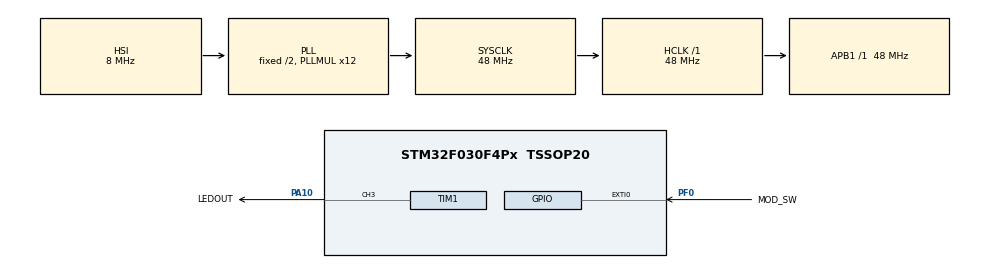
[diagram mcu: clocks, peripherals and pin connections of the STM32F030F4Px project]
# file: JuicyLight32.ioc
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Dma.Request0=TIM1_CH3/UP
Dma.TIM1_CH3/UP.0.Direction=DMA_MEMORY_TO_PERIPH
Dma.TIM1_CH3/UP.0.Instance=DMA1_Channel5
Dma.TIM1_CH3/UP.0.MemDataAlignment=DMA_MDATAALIGN_BYTE
Dma.TIM1_CH3/UP.0.MemInc=DMA_MINC_ENABLE
Dma.TIM1_CH3/UP.0.Mode=DMA_NORMAL
Dma.TIM1_CH3/UP.0.PeriphDataAlignment=DMA_PDATAALIGN_HALFWORD
Dma.TIM1_CH3/UP.0.PeriphInc=DMA_PINC_DISABLE
Dma.TIM1_CH3/UP.0.Priority=DMA_PRIORITY_HIGH
Mcu.Family=STM32F0
Mcu.Name=STM32F030F4Px
Mcu.Package=TSSOP20
Mcu.UserConstants=PWM_PERIOD,59;PWM_HI,29;PWM_LO,14;TIM_PERIOD_80uS,4000;TIM_PERIOD_8mS,8000;TIM_PRESC_1uS,47
NVIC.DMA1_Channel4_5_IRQn=true\:0\:0\:false\:false\:true\:false\:true
NVIC.EXTI0_1_IRQn=true\:0\:0\:false\:false\:true\:true\:true
NVIC.TIM3_IRQn=true\:0\:0\:false\:false\:true\:true\:true
PA10.GPIO_Label=LEDOUT
PA10.Signal=S_TIM1_CH3
PA13.Mode=Serial_Wire
PA13.Signal=SYS_SWDIO
PA14.Mode=Serial_Wire
PA14.Signal=SYS_SWCLK
PF0-OSC_IN.GPIO_Label=MOD_SW
PF0-OSC_IN.GPIO_ModeDefaultEXTI=GPIO_MODE_IT_RISING_FALLING
PF0-OSC_IN.Signal=GPXTI0
ProjectManager.HeapSize=0x200
ProjectManager.StackSize=0x400
ProjectManager.TargetToolchain=STM32CubeIDE
RCC.AHBFreq_Value=48000000
RCC.APB1Freq_Value=48000000
RCC.APB1TimFreq_Value=48000000
RCC.HCLKFreq_Value=48000000
RCC.PLLMUL=RCC_PLL_MUL12
RCC.SYSCLKFreq_VALUE=48000000
RCC.SYSCLKSource=RCC_SYSCLKSOURCE_PLLCLK
SH.S_TIM1_CH3.0=TIM1_CH3,PWM Generation3 CH3
TIM1.AutoReloadPreload=TIM_AUTORELOAD_PRELOAD_ENABLE
TIM1.Channel-PWM\ Generation3\ CH3=TIM_CHANNEL_3
TIM1.OCPolarity_3=TIM_OCPOLARITY_LOW
TIM1.Period=PWM_PERIOD
TIM14.Period=TIM_PERIOD_80uS
TIM3.Period=TIM_PERIOD_8mS
TIM3.Prescaler=TIM_PRESC_1uS
VP_TIM14_VS_ClockSourceINT.Mode=Enable_Timer
VP_TIM1_VS_ClockSourceINT.Mode=Internal
VP_TIM3_VS_ClockSourceINT.Mode=Internal
board=custom

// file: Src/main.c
/* USER CODE BEGIN Header */
/**
  ******************************************************************************
  * @file           : main.c
  * @brief          : Main program body
  ******************************************************************************
  * @attention
  *
  * <h2><center>&copy; Copyright (c) 2019 STMicroelectronics.
  * All rights reserved.</center></h2>
  *
  * This software component is licensed by ST under BSD 3-Clause license,
  * the "License"; You may not use this file except in compliance with the
  * License. You may obtain a copy of the License at:
  *                        opensource.org/licenses/BSD-3-Clause
  *
  ******************************************************************************
  */
/* USER CODE END Header */

#include "main.h"

TIM_HandleTypeDef htim1;
TIM_HandleTypeDef htim3;
TIM_HandleTypeDef htim14;
DMA_HandleTypeDef hdma_tim1_ch3_up;

/* USER CODE BEGIN PV */
#if LEDTYPE == RGBW
const LEDDATA LEDTable[COLOR_COUNT] = {
		//			R		G		B		W
		{.rgbw = {.r=LOFF,.g=LOFF,.b=LOFF,.w=LOFF}},//COLOR_OFF,
		{.rgbw = {.r=LMAX,.g=LOFF,.b=LOFF,.w=LOFF}},//COLOR_RED,
		{.rgbw = {.r=LOFF,.g=LOFF,.b=LMAX,.w=LOFF}},//COLOR_BLUE,
		{.rgbw = {.r=LOFF,.g=LMAX,.b=LOFF,.w=LOFF}},//COLOR_GREEN,
		{.rgbw = {.r=LOFF,.g=LOFF,.b=LOFF,.w=LMAX}},//COLOR_WHITE,
#if 1	//for transaparent tube
		{.rgbw = {.r=LHLF,.g=LHLF,.b=LOFF,.w=LOFF}},//COLOR_YELLOW,
#else	//for tracing paper color collection
		{.rgbw = {.r=LHLF,.g=((LHLF/4)*3),.b=LOFF,.w=LOFF}},//COLOR_YELLOW,
#endif
		{.rgbw = {.r=LHLF,.g=LOFF,.b=LHLF,.w=LOFF}},//COLOR_MAGENTA,
		{.rgbw = {.r=LOFF,.g=LHLF,.b=LHLF,.w=LOFF}},//COLOR_CYAN,
		{.rgbw = {.r=LMAX,.g=LOFF,.b=LQTR,.w=LMIN}},//COLOR_PINK,
		{.rgbw = {.r=LMAX,.g=LQTR,.b=LOFF,.w=LOFF}},//COLOR_ORANGE,
};
#else
const LEDDATA LEDTable[COLOR_MAX] = {
	//			R		G		B
	{.rgb = {.r=LOFF,.g=LOFF,.b=LOFF}},//COLOR_OFF,
	{.rgb = {.r=LMAX,.g=LOFF,.b=LOFF}},//COLOR_RED,
	{.rgb = {.r=LOFF,.g=LOFF,.b=LMAX}},//COLOR_BLUE,
	{.rgb = {.r=LOFF,.g=LMAX,.b=LOFF}},//COLOR_GREEN,
	{.rgb = {.r=LOFF,.g=LOFF,.b=LOFF}},//COLOR_WHITE,
	{.rgb = {.r=LHLF,.g=LHLF,.b=LOFF}},//COLOR_YELLOW,
	{.rgb = {.r=LHLF,.g=LOFF,.b=LHLF}},//COLOR_MAGENTA,
	{.rgb = {.r=LOFF,.g=LHLF,.b=LHLF}},//COLOR_CYAN,
	{.rgb = {.r=LMAX,.g=LOFF,.b=LQTR}},//COLOR_PINK,
	{.rgb = {.r=LMAX,.g=LQTR,.b=LOFF}},//COLOR_ORANGE,
}
#endif

#if LED_COUNT == 10
const uint8_t	LEDRainbow[LED_COUNT]={
		COLOR_BLUE,COLOR_GREEN,COLOR_YELLOW,COLOR_ORANGE,COLOR_RED,
		COLOR_RED,COLOR_ORANGE,COLOR_YELLOW,COLOR_GREEN,COLOR_BLUE
};
#else
const uint8_t	LEDRainbow[LED_COUNT]={
//			1			2			3			4			5			6			7			8
		COLOR_WHITE,COLOR_MAGENTA,COLOR_PINK,COLOR_BLUE,COLOR_GREEN,COLOR_YELLOW,COLOR_ORANGE,COLOR_RED,
		COLOR_RED,COLOR_ORANGE,COLOR_YELLOW,COLOR_GREEN,COLOR_BLUE,COLOR_PINK,COLOR_MAGENTA,COLOR_WHITE
//			9			10			11			12			13			14			15			16

};
#endif
const uint8_t	LEDRainbowRotate[LED_COUNT]={
//			1			2			3			4			5			6			7			8
		COLOR_WHITE,COLOR_MAGENTA,COLOR_PINK,COLOR_BLUE,COLOR_GREEN,COLOR_YELLOW,COLOR_ORANGE,COLOR_RED,
		COLOR_WHITE,COLOR_MAGENTA,COLOR_PINK,COLOR_BLUE,COLOR_GREEN,COLOR_YELLOW,COLOR_ORANGE,COLOR_RED,
//			9			10			11			12			13			14			15			16

};
uint8_t		LEDColor[LED_COUNT];
uint8_t		LEDPulse[TOTAL_BITS];	//Data formed PWM width send to LED

//Mode control
uint8_t LightColor;		//Set from switch
uint8_t LightMode;
uint8_t	LightPattern = PATTERN_DYNAMIC_DD;

//For switch detection.
bool	DynamicFlag;
bool	ReleaseIgnoreFlag; //for passing 'Release' after Long press
bool	BlightFlag;
//
bool	SinglePushFlag;
bool	DoublePushFlag;
bool	LongPushFlag;
//
bool	SendFlag;

//Driven by Timer3 (8ms interval)
uint8_t Timer3Count;	//0~250 2000ms count
uint8_t Timer3Limit = TIM3_COUNT_2SEC;
uint8_t LPCount;		//Long Push count
uint8_t DPCount;		//Double Push count

/* USER CODE END PV */

void SystemClock_Config(void);
static void MX_GPIO_Init(void);
static void MX_DMA_Init(void);
static void MX_TIM1_Init(void);
static void MX_TIM3_Init(void);
static void MX_TIM14_Init(void);

/* USER CODE BEGIN 0 */

//Set LEDColor[] array to Mono color(or Rainbow)
void SetLEDColors(uint8_t mono_color){
	if (mono_color == COLOR_RAINBOW){
		memcpy(LEDColor,
				(LightPattern == PATTERN_DYNAMIC_ROTATE)?  LEDRainbowRotate:LEDRainbow,
				LED_COUNT);
	}else{
		memset(LEDColor,mono_color,LED_COUNT);
	}
	SendFlag = true;
}

//Initialization for DD pattern
void PatternDDInit(){
	LightColor = COLOR_RED;
	Timer3Limit = TIM3_COUNT_0R5S;
	SetLEDColors(LightColor);
}

// Callback function for DD pattern
void PatternDDCallBack(){
	LightColor++;
	if(LightColor >= COLOR_RAINBOW) {
		LightColor = COLOR_RED;
	}
	SetLEDColors(LightColor);
}

// Initialization function for fade pattern
void PatternRotateInit(){
	LightColor = COLOR_RAINBOW;
	SetLEDColors(LightColor);
}

// Callback function for Fade pattern
void PatternRotateCallBack(){
	uint8_t temp = LEDColor[ (LED_COUNT-1) ];
	LEDColor[ (LED_COUNT-1) ] = LEDColor[ (LED_COUNT-2) ];
	LEDColor[ (LED_COUNT-2) ] = LEDColor[ (LED_COUNT-3) ];
	LEDColor[ (LED_COUNT-3) ] = LEDColor[ (LED_COUNT-4) ];
	LEDColor[ (LED_COUNT-4) ] = LEDColor[ (LED_COUNT-5) ];
	LEDColor[ (LED_COUNT-5) ] = LEDColor[ (LED_COUNT-6) ];
	LEDColor[ (LED_COUNT-6) ] = LEDColor[ (LED_COUNT-7) ];
	LEDColor[ (LED_COUNT-7) ] = LEDColor[ (LED_COUNT-8) ];
	LEDColor[ (LED_COUNT-8) ] = LEDColor[ (LED_COUNT-9) ];
	LEDColor[ (LED_COUNT-9) ] = LEDColor[ (LED_COUNT-10) ];
	LEDColor[ (LED_COUNT-10) ] = LEDColor[ (LED_COUNT-11) ];
	LEDColor[ (LED_COUNT-11) ] = LEDColor[ (LED_COUNT-12) ];
	LEDColor[ (LED_COUNT-12) ] = LEDColor[ (LED_COUNT-13) ];
	LEDColor[ (LED_COUNT-13) ] = LEDColor[ (LED_COUNT-14) ];
	LEDColor[ (LED_COUNT-14) ] = LEDColor[ (LED_COUNT-15) ];
	LEDColor[ (LED_COUNT-15) ] = LEDColor[ (LED_COUNT-LED_COUNT) ];
	LEDColor[ (LED_COUNT-LED_COUNT) ] =	temp;
	SendFlag = true;
}

// Function pointer array for Dynamic mode callbacks
void (*fp[PATTERN_DYNAMIC_COUNT])(void)={
	PatternDDCallBack,
	PatternRotateCallBack
};

// Dynamic mode Initialization for each patterns
void DoPatternInit(){
	switch (LightPattern){
		case 	PATTERN_DYNAMIC_DD:
			PatternDDInit();
			break;
		case	PATTERN_DYNAMIC_ROTATE:
			PatternRotateInit();
			break;
		default:
			LightMode = MODE_STATIC;
			LightColor = COLOR_RED;
			SetLEDColors(LightColor);
			break;
	}
}

//make LEDPulse[] from LEDColor[]
void Color2Pulse(){
	uint16_t	pulse = 0;
	LEDDATA		leddata;

	for(uint8_t	led = 0; led < LED_COUNT; led++){
		uint8_t c = LEDColor[led];
		leddata.n = LEDTable[c].n;
		if(BlightFlag){
			if(leddata.rgbw.r > LQTR) leddata.rgbw.r |= LBRIGHT;
			if(leddata.rgbw.g > LQTR) leddata.rgbw.g |= LBRIGHT;
			if(leddata.rgbw.b > LQTR) leddata.rgbw.b |= LBRIGHT;
#if LEDTYPE == RGBW
			if(leddata.rgbw.w > LQTR) leddata.rgbw.w |= LBRIGHT;
#endif
		}
#if LEDTTYPE == RGBW
		for (uint32_t mask = 0x80000000; mask > 0; mask >>= 1){
#else //RGB(24bit)
		for (uint32_t mask = 0x80000000; mask > 0x80; mask >>= 1){
#endif
			LEDPulse[pulse++] = (leddata.n & mask)? PWM_HI:PWM_LO;
		}
	}
}

// Send pulses to LEDs rely on LEDColor[] array
void SendPulse(){

	//Convert LEDColor[] to LEDPulse[]
	Color2Pulse();

	//Send 'RESET' signal(80us > low data) for LEDs
	HAL_TIM_Base_Start(&htim14);
	htim14.Instance->SR = 0;
	while((htim14.Instance->SR & TIM_SR_UIF) == 0)
		;	//wait until timer up.
	HAL_TIM_Base_Stop(&htim14);
	//End of RESET

	//Start DMA
	htim1.Instance->CNT = PWM_HI + 1;
	HAL_TIM_PWM_Start_DMA(&htim1, TIM_CHANNEL_3,(uint32_t *) LEDPulse, TOTAL_BITS);
}

// 'Single Pushed' event function
void SinglePushed() {
	if(LightMode == MODE_DYNAMIC){
		LightPattern++;
		if(LightPattern >= PATTERN_DYNAMIC_COUNT) {
			LightPattern = PATTERN_DYNAMIC_DD;
		}
		DoPatternInit();
	}else if(LightMode == MODE_STATIC){
		LightColor++;
		if ( LightColor > (COLOR_COUNT-1) ) {
			LightColor = COLOR_OFF;
			HAL_TIM_Base_Stop_IT(&htim3);
		}
		SetLEDColors(LightColor);
	}
}

// 'Double Pushed' event function
void DoublePushed(){
	LightMode++;
	if(LightMode > (MODE_COUNT-1) ){
		LightMode = MODE_STATIC;
		LightColor = COLOR_OFF;
		SetLEDColors(LightColor);
		return;
	}
	DoPatternInit();
}

// 'Long pushed' event function
void LongPushed(){

	BlightFlag = (BlightFlag)? false:true;
	SendFlag = true;
}
/* USER CODE END 0 */

int main(void)
{

  /* MCU Configuration--------------------------------------------------------*/

  /* Reset of all peripherals, Initializes the Flash interface and the Systick. */
  HAL_Init();

  /* Configure the system clock */
  SystemClock_Config();

  /* Initialize all configured peripherals */
  MX_GPIO_Init();
  MX_DMA_Init();
  MX_TIM1_Init();
  MX_TIM3_Init();
  MX_TIM14_Init();
  /* USER CODE BEGIN 2 */
  SinglePushFlag = false;
  DoublePushFlag = false;
  SendFlag = false;
  LightColor = COLOR_OFF;
  LightMode = MODE_STATIC;
  LongPushFlag = false;
  ReleaseIgnoreFlag = false;
  DynamicFlag = false;
  BlightFlag = false;
  LPCount = LPCOUNT_STOP;	//Timer Stopped
  DPCount = TIM3_COUNT_1SEC;
  /* USER CODE END 2 */

  /* Infinite loop */
  /* USER CODE BEGIN WHILE */
  SetLEDColors(COLOR_OFF);
  while (1)
  {
    /* USER CODE END WHILE */

    /* USER CODE BEGIN 3 */
	  if(SinglePushFlag){
		  SinglePushed();
		  SinglePushFlag = false;
	  }else if(DoublePushFlag){
		  DoublePushed();
		  DoublePushFlag = false;
	  }
	  if(SendFlag){
		  SendPulse();
		  SendFlag = false;
	  }
      if (LongPushFlag) {
          LongPushed();
          LongPushFlag = false;
      }

      HAL_SuspendTick();
#ifdef DEBUG
	#if 0 //Not exist MCUDBG_CR.sleep bit for STM32F0
		  HAL_DBGMCU_EnableDBGSleepMode();
	#endif
#endif
      HAL_PWR_EnterSLEEPMode(PWR_LOWPOWERREGULATOR_ON, PWR_SLEEPENTRY_WFI);
      HAL_ResumeTick();

  }
  /* USER CODE END 3 */
}

void SystemClock_Config(void)
{
  RCC_OscInitTypeDef RCC_OscInitStruct = {0};
  RCC_ClkInitTypeDef RCC_ClkInitStruct = {0};

  /** Initializes the CPU, AHB and APB busses clocks
  */
  RCC_OscInitStruct.OscillatorType = RCC_OSCILLATORTYPE_HSI;
  RCC_OscInitStruct.HSIState = RCC_HSI_ON;
  RCC_OscInitStruct.HSICalibrationValue = RCC_HSICALIBRATION_DEFAULT;
  RCC_OscInitStruct.PLL.PLLState = RCC_PLL_ON;
  RCC_OscInitStruct.PLL.PLLSource = RCC_PLLSOURCE_HSI;
  RCC_OscInitStruct.PLL.PLLMUL = RCC_PLL_MUL12;
  RCC_OscInitStruct.PLL.PREDIV = RCC_PREDIV_DIV1;
  if (HAL_RCC_OscConfig(&RCC_OscInitStruct) != HAL_OK)
  {
    Error_Handler();
  }
  /** Initializes the CPU, AHB and APB busses clocks
  */
  RCC_ClkInitStruct.ClockType = RCC_CLOCKTYPE_HCLK|RCC_CLOCKTYPE_SYSCLK
                              |RCC_CLOCKTYPE_PCLK1;
  RCC_ClkInitStruct.SYSCLKSource = RCC_SYSCLKSOURCE_PLLCLK;
  RCC_ClkInitStruct.AHBCLKDivider = RCC_SYSCLK_DIV1;
  RCC_ClkInitStruct.APB1CLKDivider = RCC_HCLK_DIV1;

  if (HAL_RCC_ClockConfig(&RCC_ClkInitStruct, FLASH_LATENCY_1) != HAL_OK)
  {
    Error_Handler();
  }
}

static void MX_TIM1_Init(void)
{

  TIM_ClockConfigTypeDef sClockSourceConfig = {0};
  TIM_MasterConfigTypeDef sMasterConfig = {0};
  TIM_OC_InitTypeDef sConfigOC = {0};
  TIM_BreakDeadTimeConfigTypeDef sBreakDeadTimeConfig = {0};

  htim1.Instance = TIM1;
  htim1.Init.Prescaler = 0;
  htim1.Init.CounterMode = TIM_COUNTERMODE_UP;
  htim1.Init.Period = PWM_PERIOD;
  htim1.Init.ClockDivision = TIM_CLOCKDIVISION_DIV1;
  htim1.Init.RepetitionCounter = 0;
  htim1.Init.AutoReloadPreload = TIM_AUTORELOAD_PRELOAD_ENABLE;
  if (HAL_TIM_Base_Init(&htim1) != HAL_OK)
  {
    Error_Handler();
  }
  sClockSourceConfig.ClockSource = TIM_CLOCKSOURCE_INTERNAL;
  if (HAL_TIM_ConfigClockSource(&htim1, &sClockSourceConfig) != HAL_OK)
  {
    Error_Handler();
  }
  if (HAL_TIM_PWM_Init(&htim1) != HAL_OK)
  {
    Error_Handler();
  }
  sMasterConfig.MasterOutputTrigger = TIM_TRGO_RESET;
  sMasterConfig.MasterSlaveMode = TIM_MASTERSLAVEMODE_DISABLE;
  if (HAL_TIMEx_MasterConfigSynchronization(&htim1, &sMasterConfig) != HAL_OK)
  {
    Error_Handler();
  }
  sConfigOC.OCMode = TIM_OCMODE_PWM1;
  sConfigOC.Pulse = 0;
  sConfigOC.OCPolarity = TIM_OCPOLARITY_LOW;
  sConfigOC.OCNPolarity = TIM_OCNPOLARITY_HIGH;
  sConfigOC.OCFastMode = TIM_OCFAST_DISABLE;
  sConfigOC.OCIdleState = TIM_OCIDLESTATE_RESET;
  sConfigOC.OCNIdleState = TIM_OCNIDLESTATE_RESET;
  if (HAL_TIM_PWM_ConfigChannel(&htim1, &sConfigOC, TIM_CHANNEL_3) != HAL_OK)
  {
    Error_Handler();
  }
  sBreakDeadTimeConfig.OffStateRunMode = TIM_OSSR_DISABLE;
  sBreakDeadTimeConfig.OffStateIDLEMode = TIM_OSSI_DISABLE;
  sBreakDeadTimeConfig.LockLevel = TIM_LOCKLEVEL_OFF;
  sBreakDeadTimeConfig.DeadTime = 0;
  sBreakDeadTimeConfig.BreakState = TIM_BREAK_DISABLE;
  sBreakDeadTimeConfig.BreakPolarity = TIM_BREAKPOLARITY_HIGH;
  sBreakDeadTimeConfig.AutomaticOutput = TIM_AUTOMATICOUTPUT_DISABLE;
  if (HAL_TIMEx_ConfigBreakDeadTime(&htim1, &sBreakDeadTimeConfig) != HAL_OK)
  {
    Error_Handler();
  }
  HAL_TIM_MspPostInit(&htim1);

}

static void MX_TIM3_Init(void)
{

  TIM_ClockConfigTypeDef sClockSourceConfig = {0};
  TIM_MasterConfigTypeDef sMasterConfig = {0};

  htim3.Instance = TIM3;
  htim3.Init.Prescaler = TIM_PRESC_1uS;
  htim3.Init.CounterMode = TIM_COUNTERMODE_UP;
  htim3.Init.Period = TIM_PERIOD_8mS;
  htim3.Init.ClockDivision = TIM_CLOCKDIVISION_DIV1;
  htim3.Init.AutoReloadPreload = TIM_AUTORELOAD_PRELOAD_DISABLE;
  if (HAL_TIM_Base_Init(&htim3) != HAL_OK)
  {
    Error_Handler();
  }
  sClockSourceConfig.ClockSource = TIM_CLOCKSOURCE_INTERNAL;
  if (HAL_TIM_ConfigClockSource(&htim3, &sClockSourceConfig) != HAL_OK)
  {
    Error_Handler();
  }
  sMasterConfig.MasterOutputTrigger = TIM_TRGO_RESET;
  sMasterConfig.MasterSlaveMode = TIM_MASTERSLAVEMODE_DISABLE;
  if (HAL_TIMEx_MasterConfigSynchronization(&htim3, &sMasterConfig) != HAL_OK)
  {
    Error_Handler();
  }

}

static void MX_TIM14_Init(void)
{

  htim14.Instance = TIM14;
  htim14.Init.Prescaler = 0;
  htim14.Init.CounterMode = TIM_COUNTERMODE_UP;
  htim14.Init.Period = TIM_PERIOD_80uS;
  htim14.Init.ClockDivision = TIM_CLOCKDIVISION_DIV1;
  htim14.Init.AutoReloadPreload = TIM_AUTORELOAD_PRELOAD_DISABLE;
  if (HAL_TIM_Base_Init(&htim14) != HAL_OK)
  {
    Error_Handler();
  }

}

static void MX_DMA_Init(void)
{
  /* DMA controller clock enable */
  __HAL_RCC_DMA1_CLK_ENABLE();

  /* DMA interrupt init */
  /* DMA1_Channel4_5_IRQn interrupt configuration */
  HAL_NVIC_SetPriority(DMA1_Channel4_5_IRQn, 0, 0);
  HAL_NVIC_EnableIRQ(DMA1_Channel4_5_IRQn);

}

static void MX_GPIO_Init(void)
{
  GPIO_InitTypeDef GPIO_InitStruct = {0};

  /* GPIO Ports Clock Enable */
  __HAL_RCC_GPIOF_CLK_ENABLE();
  __HAL_RCC_GPIOA_CLK_ENABLE();

  /*Configure GPIO pin : MOD_SW_Pin */
  GPIO_InitStruct.Pin = MOD_SW_Pin;
  GPIO_InitStruct.Mode = GPIO_MODE_IT_RISING_FALLING;
  GPIO_InitStruct.Pull = GPIO_NOPULL;
  HAL_GPIO_Init(MOD_SW_GPIO_Port, &GPIO_InitStruct);

  /* EXTI interrupt init*/
  HAL_NVIC_SetPriority(EXTI0_1_IRQn, 0, 0);
  HAL_NVIC_EnableIRQ(EXTI0_1_IRQn);

}

void Error_Handler(void)
{
}

/************************ (C) COPYRIGHT STMicroelectronics *****END OF FILE****/
